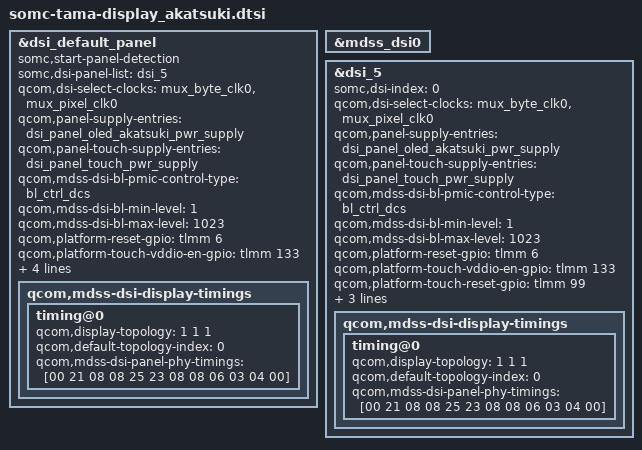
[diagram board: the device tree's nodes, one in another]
// SPDX-License-Identifier: GPL-2.0-only
/*
 * Copyright (c) 2015-2017, The Linux Foundation. All rights reserved.
 */

&dsi_default_panel {
	somc,start-panel-detection;
	somc,dsi-panel-list = <&dsi_5>;
	qcom,dsi-select-clocks = "mux_byte_clk0", "mux_pixel_clk0";
	qcom,panel-supply-entries = <&dsi_panel_oled_akatsuki_pwr_supply>;
	qcom,panel-touch-supply-entries = <&dsi_panel_touch_pwr_supply>;
	/delete-property/ qcom,panel-vspvsn-supply-entries;
	qcom,mdss-dsi-bl-pmic-control-type = "bl_ctrl_dcs";
	qcom,mdss-dsi-bl-min-level = <1>;
	qcom,mdss-dsi-bl-max-level = <1023>;
	qcom,platform-reset-gpio = <&tlmm 6 0>;
	qcom,platform-touch-vddio-en-gpio = <&tlmm 133 0>;
	qcom,platform-touch-reset-gpio = <&tlmm 99 0>;
	somc,disp-err-flag-gpio = <&tlmm 44 0>;
	qcom,mdss-dsi-t-clk-post = <0x0E>;
	qcom,mdss-dsi-t-clk-pre = <0x33>;
	qcom,mdss-dsi-display-timings {
		timing@0 {
			qcom,display-topology = <1 1 1>;
			qcom,default-topology-index = <0>;
			qcom,mdss-dsi-panel-phy-timings = [00 21 08 08 25 23 08 08 06 03 04 00];
		};
	};
};

&mdss_dsi0 {
	/delete-property/ qcom,null-insertion-enabled;
};

&dsi_5 {
	somc,dsi-index = <0>;
	qcom,dsi-select-clocks = "mux_byte_clk0", "mux_pixel_clk0";
	qcom,panel-supply-entries = <&dsi_panel_oled_akatsuki_pwr_supply>;
	qcom,panel-touch-supply-entries = <&dsi_panel_touch_pwr_supply>;
	/delete-property/ qcom,panel-vspvsn-supply-entries;
	qcom,mdss-dsi-bl-pmic-control-type = "bl_ctrl_dcs";
	qcom,mdss-dsi-bl-min-level = <1>;
	qcom,mdss-dsi-bl-max-level = <1023>;
	qcom,platform-reset-gpio = <&tlmm 6 0>;
	qcom,platform-touch-vddio-en-gpio = <&tlmm 133 0>;
	qcom,platform-touch-reset-gpio = <&tlmm 99 0>;
	somc,disp-err-flag-gpio = <&tlmm 44 0>;
	qcom,mdss-dsi-t-clk-post = <0x0E>;
	qcom,mdss-dsi-t-clk-pre = <0x33>;
	qcom,mdss-dsi-display-timings {
		timing@0 {
			qcom,display-topology = <1 1 1>;
			qcom,default-topology-index = <0>;
			qcom,mdss-dsi-panel-phy-timings = [00 21 08 08 25 23 08 08 06 03 04 00];
		};
	};
};
